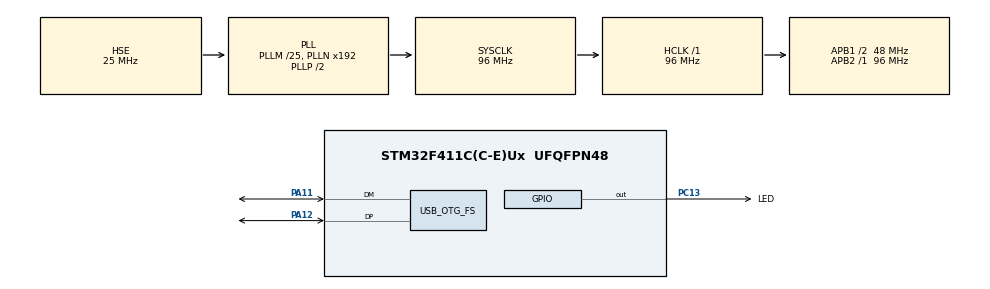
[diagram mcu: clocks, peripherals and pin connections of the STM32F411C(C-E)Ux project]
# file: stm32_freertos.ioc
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AL94.I-CUBE-USBD-COMPOSITE.1.0.3.CompositeCcUSBJjCOMPOSITEJjCDCIiACM=true
AL94.I-CUBE-USBD-COMPOSITE.1.0.3.CompositeCcUSBJjCOMPOSITEJjCOMPOSITE=true
AL94.I-CUBE-USBD-COMPOSITE.1.0.3.CompositeCcUSBJjCOMPOSITEJjCore=true
AL94.I-CUBE-USBD-COMPOSITE.1.0.3.CompositeCcUSBJjCOMPOSITEJjHIDIiCUSTOM=true
AL94.I-CUBE-USBD-COMPOSITE.1.0.3._USBD_USE_CDC_ACM=true
AL94.I-CUBE-USBD-COMPOSITE.1.0.3._USBD_USE_HID_CUSTOM=true
Mcu.Family=STM32F4
Mcu.Name=STM32F411C(C-E)Ux
Mcu.Package=UFQFPN48
NVIC.OTG_FS_IRQn=true\:0\:0\:false\:false\:true\:true\:true\:true
NVIC.PriorityGroup=NVIC_PRIORITYGROUP_4
NVIC.TIM1_UP_TIM10_IRQn=true\:15\:0\:false\:false\:true\:false\:true\:true
NVIC.TimeBase=TIM1_UP_TIM10_IRQn
NVIC.TimeBaseIP=TIM10
PA11.Mode=Device_Only
PA11.Signal=USB_OTG_FS_DM
PA12.Mode=Device_Only
PA12.Signal=USB_OTG_FS_DP
PA13.Mode=Serial_Wire
PA13.Signal=SYS_JTMS-SWDIO
PA14.Mode=Serial_Wire
PA14.Signal=SYS_JTCK-SWCLK
PC13-ANTI_TAMP.GPIO_Label=LED
PC13-ANTI_TAMP.Signal=GPIO_Output
PH0\ -\ OSC_IN.Mode=HSE-External-Oscillator
PH0\ -\ OSC_IN.Signal=RCC_OSC_IN
PH1\ -\ OSC_OUT.Mode=HSE-External-Oscillator
PH1\ -\ OSC_OUT.Signal=RCC_OSC_OUT
ProjectManager.HeapSize=0x200
ProjectManager.StackSize=0x400
ProjectManager.TargetToolchain=STM32CubeIDE
RCC.48MHZClocksFreq_Value=48000000
RCC.AHBFreq_Value=96000000
RCC.APB1CLKDivider=RCC_HCLK_DIV2
RCC.APB1Freq_Value=48000000
RCC.APB1TimFreq_Value=96000000
RCC.APB2Freq_Value=96000000
RCC.APB2TimFreq_Value=96000000
RCC.CortexFreq_Value=96000000
RCC.HCLKFreq_Value=96000000
RCC.HSE_VALUE=25000000
RCC.HSI_VALUE=16000000
RCC.LSE_VALUE=32768
RCC.PLLM=25
RCC.SYSCLKFreq_VALUE=96000000
RCC.SYSCLKSource=RCC_SYSCLKSOURCE_PLLCLK
RCC.VCOOutputFreq_Value=192000000
USB_OTG_FS.VirtualMode=Device_Only
VP_AL94.I-CUBE-USBD-COMPOSITE_VS_USBJjComposite_1.0.0_1.0.3.Mode=USBJjComposite
VP_SYS_VS_tim10.Mode=TIM10
board=custom

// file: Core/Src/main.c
/* USER CODE BEGIN Header */
/**
  ******************************************************************************
  * @file           : main.c
  * @brief          : Main program body
  ******************************************************************************
  * @attention
  *
  * Copyright (c) 2023 STMicroelectronics.
  * All rights reserved.
  *
  * This software is licensed under terms that can be found in the LICENSE file
  * in the root directory of this software component.
  * If no LICENSE file comes with this software, it is provided AS-IS.
  *
  ******************************************************************************
  */
/* USER CODE END Header */
#include "main.h"
#include "usb_otg.h"
#include "gpio.h"

/* USER CODE BEGIN Includes */
#include "task_FreeRtos.h"
/* USER CODE END Includes */

void SystemClock_Config(void);
/* USER CODE BEGIN PFP */
void MX_USB_DEVICE_Init();
/* USER CODE END PFP */

int main(void)
{

  /* MCU Configuration--------------------------------------------------------*/

  /* Reset of all peripherals, Initializes the Flash interface and the Systick. */
  HAL_Init();

  /* Configure the system clock */
  SystemClock_Config();

  /* Initialize all configured peripherals */
  MX_GPIO_Init();

  /* USER CODE BEGIN 2 */
	xTaskCreate(Blink1_Task, "Blink1", 128, NULL, 1, NULL);
	vTaskStartScheduler();

  /* USER CODE END 2 */

  /* Infinite loop */
  /* USER CODE BEGIN WHILE */
  while (1)
  {
//	  HAL_GPIO_TogglePin(LED_GPIO_Port, LED_Pin);
//	  HAL_Delay(500);
    /* USER CODE END WHILE */

  }
}

void SystemClock_Config(void)
{
  RCC_OscInitTypeDef RCC_OscInitStruct = {0};
  RCC_ClkInitTypeDef RCC_ClkInitStruct = {0};

  /** Configure the main internal regulator output voltage
  */
  __HAL_RCC_PWR_CLK_ENABLE();
  __HAL_PWR_VOLTAGESCALING_CONFIG(PWR_REGULATOR_VOLTAGE_SCALE1);

  /** Initializes the RCC Oscillators according to the specified parameters
  * in the RCC_OscInitTypeDef structure.
  */
  RCC_OscInitStruct.OscillatorType = RCC_OSCILLATORTYPE_HSE;
  RCC_OscInitStruct.HSEState = RCC_HSE_ON;
  RCC_OscInitStruct.PLL.PLLState = RCC_PLL_ON;
  RCC_OscInitStruct.PLL.PLLSource = RCC_PLLSOURCE_HSE;
  RCC_OscInitStruct.PLL.PLLM = 25;
  RCC_OscInitStruct.PLL.PLLN = 192;
  RCC_OscInitStruct.PLL.PLLP = RCC_PLLP_DIV2;
  RCC_OscInitStruct.PLL.PLLQ = 4;
  if (HAL_RCC_OscConfig(&RCC_OscInitStruct) != HAL_OK)
  {
    Error_Handler();
  }

  /** Initializes the CPU, AHB and APB buses clocks
  */
  RCC_ClkInitStruct.ClockType = RCC_CLOCKTYPE_HCLK|RCC_CLOCKTYPE_SYSCLK
                              |RCC_CLOCKTYPE_PCLK1|RCC_CLOCKTYPE_PCLK2;
  RCC_ClkInitStruct.SYSCLKSource = RCC_SYSCLKSOURCE_PLLCLK;
  RCC_ClkInitStruct.AHBCLKDivider = RCC_SYSCLK_DIV1;
  RCC_ClkInitStruct.APB1CLKDivider = RCC_HCLK_DIV2;
  RCC_ClkInitStruct.APB2CLKDivider = RCC_HCLK_DIV1;

  if (HAL_RCC_ClockConfig(&RCC_ClkInitStruct, FLASH_LATENCY_3) != HAL_OK)
  {
    Error_Handler();
  }
}

void HAL_TIM_PeriodElapsedCallback(TIM_HandleTypeDef *htim)
{
  if (htim->Instance == TIM10) {
    HAL_IncTick();
  }
}

void Error_Handler(void)
{
  __disable_irq();
  while (1)
  {
  }
}
